VERSION ""

NS_ :

BS_:

BU_: Pedal_Box

BO_ 1648 Pedal_Box_Analog: 3 Pedal_Box
 SG_ DAMPER_FL : 0|12@1+ (0.0008058608058608059,0) [0|3.3] "V" Vector__XXX
 SG_ DAMPER_FR : 12|12@1+ (0.0008058608058608059,0) [0|3.3] "V" Vector__XXX

BO_ 1653 Pedal_Box_Digital: 1 Pedal_Box
 SG_ BSPD_STATUS : 0|1@1+ (1,0) [0|1] "bool" Vector__XXX
 SG_ GPS_PPS : 1|1@1+ (1,0) [0|1] "bool" Vector__XXX

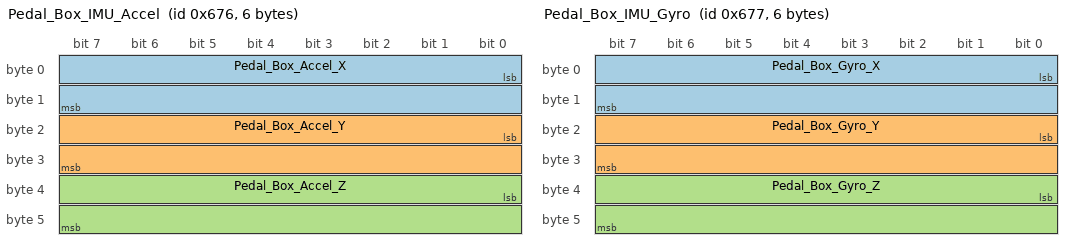
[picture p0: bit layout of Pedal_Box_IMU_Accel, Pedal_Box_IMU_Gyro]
BO_ 1654 Pedal_Box_IMU_Accel: 6 Pedal_Box
 SG_ Pedal_Box_Accel_X : 0|16@1- (0.000122,0) [-4|4] "g" Vector__XXX
 SG_ Pedal_Box_Accel_Y : 16|16@1- (0.000122,0) [-4|4] "g" Vector__XXX
 SG_ Pedal_Box_Accel_Z : 32|16@1- (0.000122,0) [-4|4] "g" Vector__XXX

BO_ 1655 Pedal_Box_IMU_Gyro: 6 Pedal_Box
 SG_ Pedal_Box_Gyro_X : 0|16@1- (0.0175,0) [-500|500] "dps" Vector__XXX
 SG_ Pedal_Box_Gyro_Y : 16|16@1- (0.0175,0) [-500|500] "dps" Vector__XXX
 SG_ Pedal_Box_Gyro_Z : 32|16@1- (0.0175,0) [-500|500] "dps" Vector__XXX

BO_ 1656 Pedal_Box_Temp: 4 Pedal_Box
 SG_ Pedal_Box_IMU_Temp : 0|16@1- (0.00390625,25) [-40|85] "degC" Vector__XXX
 SG_ Pedal_Box_Ambient_Temp : 16|16@1- (0.0625,0) [-55|125] "degC" Vector__XXX

BO_ 1657 Pedal_Box_Status: 1 Pedal_Box
 SG_ Pedal_Box_ISM330_OK : 0|1@1+ (1,0) [0|1] "" Vector__XXX
 SG_ Pedal_Box_MCP9800_OK : 1|1@1+ (1,0) [0|1] "" Vector__XXX
